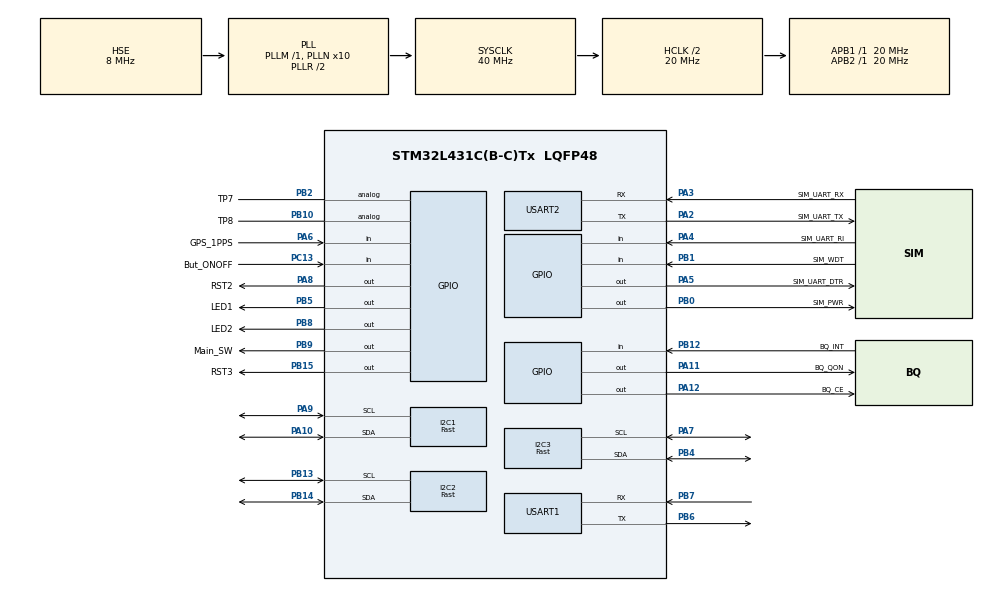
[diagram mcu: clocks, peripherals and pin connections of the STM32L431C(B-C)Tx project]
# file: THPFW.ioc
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ADC1.Channel-2\#ChannelRegularConversion=ADC_CHANNEL_TEMPSENSOR
ADC1.ClockPrescaler=ADC_CLOCK_ASYNC_DIV2
ADC1.ContinuousConvMode=ENABLE
ADC1.DMAContinuousRequests=ENABLE
ADC1.NbrOfConversion=1
ADC1.NbrOfConversionFlag=1
ADC1.OffsetNumber-2\#ChannelRegularConversion=ADC_OFFSET_NONE
ADC1.OversamplingMode=ENABLE
ADC1.Rank-2\#ChannelRegularConversion=1
ADC1.Ratio=ADC_OVERSAMPLING_RATIO_16
ADC1.SamplingTime-2\#ChannelRegularConversion=ADC_SAMPLETIME_640CYCLES_5
ADC1.master=1
CRC.CRCLength=CRC_POLYLENGTH_8B
CRC.DefaultInitValueUse=DEFAULT_INIT_VALUE_DISABLE
CRC.DefaultPolynomialUse=DEFAULT_POLYNOMIAL_DISABLE
CRC.GeneratingPolynomial=X5+X4+X0
CRC.InitValue=0xFF
Dma.ADC1.0.Direction=DMA_PERIPH_TO_MEMORY
Dma.ADC1.0.Instance=DMA1_Channel1
Dma.ADC1.0.MemDataAlignment=DMA_MDATAALIGN_HALFWORD
Dma.ADC1.0.MemInc=DMA_MINC_ENABLE
Dma.ADC1.0.Mode=DMA_CIRCULAR
Dma.ADC1.0.PeriphDataAlignment=DMA_PDATAALIGN_HALFWORD
Dma.ADC1.0.PeriphInc=DMA_PINC_DISABLE
Dma.ADC1.0.Priority=DMA_PRIORITY_LOW
Dma.Request0=ADC1
FREERTOS.INCLUDE_eTaskGetState=1
FREERTOS.INCLUDE_vTaskDelayUntil=1
FREERTOS.MEMORY_ALLOCATION=0
FREERTOS.Tasks01=defaultTask,-3,128,StartDefaultTask,Default,NULL,Dynamic,NULL,NULL;THPMainTask,0,512,THP_MainTask,As external,NULL,Dynamic,NULL,NULL
FREERTOS.configENABLE_FPU=1
FREERTOS.configMINIMAL_STACK_SIZE=128
FREERTOS.configTOTAL_HEAP_SIZE=16384
FREERTOS.configUSE_NEWLIB_REENTRANT=1
FREERTOS.configUSE_TASK_NOTIFICATIONS=1
FREERTOS.configUSE_TICKLESS_IDLE=1
I2C1.I2C_Speed_Mode=I2C_Fast
I2C1.Timing=0x00301347
I2C2.I2C_Speed_Mode=I2C_Fast
I2C2.NoStretchMode=I2C_NOSTRETCH_ENABLE
I2C2.Timing=0x00301347
I2C3.I2C_Speed_Mode=I2C_Fast
I2C3.NoStretchMode=I2C_NOSTRETCH_ENABLE
I2C3.Timing=0x00301347
Mcu.Family=STM32L4
Mcu.Name=STM32L431C(B-C)Tx
Mcu.Package=LQFP48
NVIC.DMA1_Channel1_IRQn=true\:5\:0\:false\:false\:true\:true\:false\:true\:true
NVIC.PriorityGroup=NVIC_PRIORITYGROUP_4
NVIC.RCC_IRQn=true\:5\:0\:false\:false\:false\:true\:true\:false\:false
NVIC.TIM7_IRQn=true\:15\:0\:false\:false\:true\:false\:false\:true\:true
NVIC.TimeBase=TIM7_IRQn
NVIC.TimeBaseIP=TIM7
NVIC.USART1_IRQn=true\:5\:0\:false\:true\:true\:1\:true\:true\:true\:true
NVIC.USART2_IRQn=true\:5\:0\:false\:true\:true\:2\:true\:true\:true\:true
PA0.GPIO_Label=Tamp
PA0.Mode=SYS_WakeUp0
PA0.Signal=SYS_WKUP1
PA10.GPIO_Pu=GPIO_PULLUP
PA10.Mode=I2C
PA10.Signal=I2C1_SDA
PA11.GPIO_Label=BQ_QON
PA11.Signal=GPIO_Output
PA12.GPIO_Label=BQ_CE
PA12.Signal=GPIO_Output
PA13\ (JTMS-SWDIO).Mode=Serial_Wire
PA13\ (JTMS-SWDIO).Signal=SYS_JTMS-SWDIO
PA14\ (JTCK-SWCLK).Mode=Serial_Wire
PA14\ (JTCK-SWCLK).Signal=SYS_JTCK-SWCLK
PA2.GPIO_Label=SIM_UART_TX
PA2.GPIO_Speed=GPIO_SPEED_FREQ_HIGH
PA2.Mode=Asynchronous
PA2.Signal=USART2_TX
PA3.GPIO_Label=SIM_UART_RX
PA3.GPIO_PuPd=GPIO_PULLUP
PA3.GPIO_Speed=GPIO_SPEED_FREQ_HIGH
PA3.Mode=Asynchronous
PA3.Signal=USART2_RX
PA4.GPIO_Label=SIM_UART_RI
PA4.Signal=GPIO_Input
PA5.GPIO_Label=SIM_UART_DTR
PA5.PinState=GPIO_PIN_SET
PA5.Signal=GPIO_Output
PA6.GPIO_Label=GPS_1PPS
PA6.GPIO_PuPd=GPIO_PULLUP
PA6.Signal=GPIO_Input
PA7.GPIO_Pu=GPIO_PULLUP
PA7.Mode=I2C
PA7.Signal=I2C3_SCL
PA8.GPIO_Label=RST2
PA8.GPIO_PuPd=GPIO_PULLUP
PA8.Signal=GPIO_Output
PA9.GPIO_Pu=GPIO_PULLUP
PA9.Mode=I2C
PA9.Signal=I2C1_SCL
PB0.GPIO_Label=SIM_PWR
PB0.Signal=GPIO_Output
PB1.GPIO_Label=SIM_WDT
PB1.GPIO_PuPd=GPIO_PULLUP
PB1.Signal=GPIO_Input
PB10.GPIO_Label=TP8
PB10.Signal=GPIO_Analog
PB12.GPIO_Label=BQ_INT
PB12.GPIO_PuPd=GPIO_PULLUP
PB12.Signal=GPIO_Input
PB13.GPIO_Pu=GPIO_PULLUP
PB13.Mode=I2C
PB13.Signal=I2C2_SCL
PB14.GPIO_Pu=GPIO_PULLUP
PB14.Mode=I2C
PB14.Signal=I2C2_SDA
PB15.GPIO_Label=RST3
PB15.GPIO_PuPd=GPIO_NOPULL
PB15.Signal=GPIO_Output
PB2.GPIO_Label=TP7
PB2.Signal=GPIO_Analog
PB4\ (NJTRST).GPIO_Pu=GPIO_PULLUP
PB4\ (NJTRST).Mode=I2C
PB4\ (NJTRST).Signal=I2C3_SDA
PB5.GPIO_Label=LED1
PB5.PinState=GPIO_PIN_SET
PB5.Signal=GPIO_Output
PB6.GPIO_Speed=GPIO_SPEED_FREQ_HIGH
PB6.Mode=Asynchronous
PB6.Signal=USART1_TX
PB7.GPIO_PuPd=GPIO_PULLUP
PB7.GPIO_Speed=GPIO_SPEED_FREQ_HIGH
PB7.Mode=Asynchronous
PB7.Signal=USART1_RX
PB8.GPIO_Label=LED2
PB8.PinState=GPIO_PIN_SET
PB8.Signal=GPIO_Output
PB9.GPIO_Label=Main_SW
PB9.GPIO_PuPd=GPIO_PULLDOWN
PB9.Signal=GPIO_Output
PC13.GPIO_Label=But_ONOFF
PC13.GPIO_PuPd=GPIO_PULLDOWN
PC13.Signal=GPIO_Input
PH0-OSC_IN\ (PH0).Mode=HSE-External-Oscillator
PH0-OSC_IN\ (PH0).Signal=RCC_OSC_IN
PH1-OSC_OUT\ (PH1).Mode=HSE-External-Oscillator
PH1-OSC_OUT\ (PH1).Signal=RCC_OSC_OUT
ProjectManager.HeapSize=0x200
ProjectManager.StackSize=0x400
ProjectManager.TargetToolchain=STM32CubeIDE
RCC.ADCFreq_Value=32000000
RCC.AHBCLKDivider=RCC_SYSCLK_DIV2
RCC.AHBFreq_Value=20000000
RCC.APB1Freq_Value=20000000
RCC.APB1TimFreq_Value=20000000
RCC.APB2Freq_Value=20000000
RCC.APB2TimFreq_Value=20000000
RCC.CortexFreq_Value=20000000
RCC.HCLKFreq_Value=20000000
RCC.HSE_VALUE=8000000
RCC.HSI48_VALUE=48000000
RCC.HSI_VALUE=16000000
RCC.I2C1CLockSelection=RCC_I2C1CLKSOURCE_SYSCLK
RCC.I2C2CLockSelection=RCC_I2C2CLKSOURCE_SYSCLK
RCC.I2C3CLockSelection=RCC_I2C3CLKSOURCE_SYSCLK
RCC.LSE_VALUE=32768
RCC.MSI_VALUE=4000000
RCC.PLLN=10
RCC.PLLSourceVirtual=RCC_PLLSOURCE_HSE
RCC.SYSCLKFreq_VALUE=40000000
RCC.SYSCLKSource=RCC_SYSCLKSOURCE_PLLCLK
RCC.USART1CLockSelection=RCC_USART1CLKSOURCE_SYSCLK
RCC.USART2CLockSelection=RCC_USART2CLKSOURCE_SYSCLK
RCC.VCOOutputFreq_Value=80000000
USART1.VirtualMode-Asynchronous=VM_ASYNC
USART2.VirtualMode-Asynchronous=VM_ASYNC
VP_ADC1_TempSens_Input.Mode=IN-TempSens
VP_CRC_VS_CRC.Mode=CRC_Activate
VP_FREERTOS_VS_CMSIS_V1.Mode=CMSIS_V1
VP_SYS_VS_tim7.Mode=TIM7
board=custom

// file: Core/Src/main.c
/* USER CODE BEGIN Header */
/**
  ******************************************************************************
  * @file           : main.c
  * @brief          : Main program body
  ******************************************************************************
  * @attention
  *
  * Copyright (c) 2024 STMicroelectronics.
  * All rights reserved.
  *
  * This software is licensed under terms that can be found in the LICENSE file
  * in the root directory of this software component.
  * If no LICENSE file comes with this software, it is provided AS-IS.
  *
  ******************************************************************************
  */
/* USER CODE END Header */
#include "main.h"
#include "cmsis_os.h"

ADC_HandleTypeDef hadc1;
DMA_HandleTypeDef hdma_adc1;

CRC_HandleTypeDef hcrc;

I2C_HandleTypeDef hi2c1;
I2C_HandleTypeDef hi2c2;
I2C_HandleTypeDef hi2c3;

UART_HandleTypeDef huart1;
UART_HandleTypeDef huart2;

osThreadId defaultTaskHandle;
osThreadId THPMainTaskHandle;

void SystemClock_Config(void);
static void MX_GPIO_Init(void);
static void MX_DMA_Init(void);
static void MX_ADC1_Init(void);
static void MX_I2C1_Init(void);
static void MX_I2C2_Init(void);
static void MX_I2C3_Init(void);
static void MX_USART1_UART_Init(void);
static void MX_USART2_UART_Init(void);
static void MX_CRC_Init(void);
void StartDefaultTask(void const * argument);
extern void THP_MainTask(void const * argument);

static void MX_NVIC_Init(void);

int main(void)
{

  /* MCU Configuration--------------------------------------------------------*/

  /* Reset of all peripherals, Initializes the Flash interface and the Systick. */
  HAL_Init();

  /* Configure the system clock */
  SystemClock_Config();

  /* Initialize all configured peripherals */
  MX_GPIO_Init();
  MX_DMA_Init();
  MX_ADC1_Init();
  MX_I2C1_Init();
  MX_I2C2_Init();
  MX_I2C3_Init();
  MX_USART1_UART_Init();
  MX_USART2_UART_Init();
  MX_CRC_Init();

  /* Initialize interrupts */
  MX_NVIC_Init();

  /* Create the thread(s) */
  /* definition and creation of defaultTask */
  osThreadDef(defaultTask, StartDefaultTask, osPriorityIdle, 0, 128);
  defaultTaskHandle = osThreadCreate(osThread(defaultTask), NULL);

  /* definition and creation of THPMainTask */
  osThreadDef(THPMainTask, THP_MainTask, osPriorityNormal, 0, 512);
  THPMainTaskHandle = osThreadCreate(osThread(THPMainTask), NULL);

  /* Start scheduler */
  osKernelStart();
  /* We should never get here as control is now taken by the scheduler */
  /* Infinite loop */
  while (1)
  {

  }
}

void SystemClock_Config(void)
{
  RCC_OscInitTypeDef RCC_OscInitStruct = {0};
  RCC_ClkInitTypeDef RCC_ClkInitStruct = {0};

  /** Configure the main internal regulator output voltage
  */
  if (HAL_PWREx_ControlVoltageScaling(PWR_REGULATOR_VOLTAGE_SCALE1) != HAL_OK)
  {
    Error_Handler();
  }

  /** Initializes the RCC Oscillators according to the specified parameters
  * in the RCC_OscInitTypeDef structure.
  */
  RCC_OscInitStruct.OscillatorType = RCC_OSCILLATORTYPE_HSE;
  RCC_OscInitStruct.HSEState = RCC_HSE_ON;
  RCC_OscInitStruct.PLL.PLLState = RCC_PLL_ON;
  RCC_OscInitStruct.PLL.PLLSource = RCC_PLLSOURCE_HSE;
  RCC_OscInitStruct.PLL.PLLM = 1;
  RCC_OscInitStruct.PLL.PLLN = 10;
  RCC_OscInitStruct.PLL.PLLP = RCC_PLLP_DIV7;
  RCC_OscInitStruct.PLL.PLLQ = RCC_PLLQ_DIV2;
  RCC_OscInitStruct.PLL.PLLR = RCC_PLLR_DIV2;
  if (HAL_RCC_OscConfig(&RCC_OscInitStruct) != HAL_OK)
  {
    Error_Handler();
  }

  /** Initializes the CPU, AHB and APB buses clocks
  */
  RCC_ClkInitStruct.ClockType = RCC_CLOCKTYPE_HCLK|RCC_CLOCKTYPE_SYSCLK
                              |RCC_CLOCKTYPE_PCLK1|RCC_CLOCKTYPE_PCLK2;
  RCC_ClkInitStruct.SYSCLKSource = RCC_SYSCLKSOURCE_PLLCLK;
  RCC_ClkInitStruct.AHBCLKDivider = RCC_SYSCLK_DIV2;
  RCC_ClkInitStruct.APB1CLKDivider = RCC_HCLK_DIV1;
  RCC_ClkInitStruct.APB2CLKDivider = RCC_HCLK_DIV1;

  if (HAL_RCC_ClockConfig(&RCC_ClkInitStruct, FLASH_LATENCY_1) != HAL_OK)
  {
    Error_Handler();
  }
}

/**
  * @brief NVIC Configuration.
  * @retval None
  */
static void MX_NVIC_Init(void)
{
  /* USART1_IRQn interrupt configuration */
  HAL_NVIC_SetPriority(USART1_IRQn, 5, 0);
  HAL_NVIC_EnableIRQ(USART1_IRQn);
  /* USART2_IRQn interrupt configuration */
  HAL_NVIC_SetPriority(USART2_IRQn, 5, 0);
  HAL_NVIC_EnableIRQ(USART2_IRQn);
}

static void MX_ADC1_Init(void)
{

  ADC_ChannelConfTypeDef sConfig = {0};

  /** Common config
  */
  hadc1.Instance = ADC1;
  hadc1.Init.ClockPrescaler = ADC_CLOCK_ASYNC_DIV2;
  hadc1.Init.Resolution = ADC_RESOLUTION_12B;
  hadc1.Init.DataAlign = ADC_DATAALIGN_RIGHT;
  hadc1.Init.ScanConvMode = ADC_SCAN_DISABLE;
  hadc1.Init.EOCSelection = ADC_EOC_SINGLE_CONV;
  hadc1.Init.LowPowerAutoWait = DISABLE;
  hadc1.Init.ContinuousConvMode = ENABLE;
  hadc1.Init.NbrOfConversion = 1;
  hadc1.Init.DiscontinuousConvMode = DISABLE;
  hadc1.Init.ExternalTrigConv = ADC_SOFTWARE_START;
  hadc1.Init.ExternalTrigConvEdge = ADC_EXTERNALTRIGCONVEDGE_NONE;
  hadc1.Init.DMAContinuousRequests = ENABLE;
  hadc1.Init.Overrun = ADC_OVR_DATA_PRESERVED;
  hadc1.Init.OversamplingMode = ENABLE;
  hadc1.Init.Oversampling.Ratio = ADC_OVERSAMPLING_RATIO_16;
  hadc1.Init.Oversampling.RightBitShift = ADC_RIGHTBITSHIFT_NONE;
  hadc1.Init.Oversampling.TriggeredMode = ADC_TRIGGEREDMODE_SINGLE_TRIGGER;
  hadc1.Init.Oversampling.OversamplingStopReset = ADC_REGOVERSAMPLING_CONTINUED_MODE;
  if (HAL_ADC_Init(&hadc1) != HAL_OK)
  {
    Error_Handler();
  }

  /** Configure Regular Channel
  */
  sConfig.Channel = ADC_CHANNEL_TEMPSENSOR;
  sConfig.Rank = ADC_REGULAR_RANK_1;
  sConfig.SamplingTime = ADC_SAMPLETIME_640CYCLES_5;
  sConfig.SingleDiff = ADC_SINGLE_ENDED;
  sConfig.OffsetNumber = ADC_OFFSET_NONE;
  sConfig.Offset = 0;
  if (HAL_ADC_ConfigChannel(&hadc1, &sConfig) != HAL_OK)
  {
    Error_Handler();
  }

}

static void MX_CRC_Init(void)
{

  hcrc.Instance = CRC;
  hcrc.Init.DefaultPolynomialUse = DEFAULT_POLYNOMIAL_DISABLE;
  hcrc.Init.DefaultInitValueUse = DEFAULT_INIT_VALUE_DISABLE;
  hcrc.Init.GeneratingPolynomial = 49;
  hcrc.Init.CRCLength = CRC_POLYLENGTH_8B;
  hcrc.Init.InitValue = 0xFF;
  hcrc.Init.InputDataInversionMode = CRC_INPUTDATA_INVERSION_NONE;
  hcrc.Init.OutputDataInversionMode = CRC_OUTPUTDATA_INVERSION_DISABLE;
  hcrc.InputDataFormat = CRC_INPUTDATA_FORMAT_BYTES;
  if (HAL_CRC_Init(&hcrc) != HAL_OK)
  {
    Error_Handler();
  }

}

static void MX_I2C1_Init(void)
{

  hi2c1.Instance = I2C1;
  hi2c1.Init.Timing = 0x00301347;
  hi2c1.Init.OwnAddress1 = 0;
  hi2c1.Init.AddressingMode = I2C_ADDRESSINGMODE_7BIT;
  hi2c1.Init.DualAddressMode = I2C_DUALADDRESS_DISABLE;
  hi2c1.Init.OwnAddress2 = 0;
  hi2c1.Init.OwnAddress2Masks = I2C_OA2_NOMASK;
  hi2c1.Init.GeneralCallMode = I2C_GENERALCALL_DISABLE;
  hi2c1.Init.NoStretchMode = I2C_NOSTRETCH_DISABLE;
  if (HAL_I2C_Init(&hi2c1) != HAL_OK)
  {
    Error_Handler();
  }

  /** Configure Analogue filter
  */
  if (HAL_I2CEx_ConfigAnalogFilter(&hi2c1, I2C_ANALOGFILTER_ENABLE) != HAL_OK)
  {
    Error_Handler();
  }

  /** Configure Digital filter
  */
  if (HAL_I2CEx_ConfigDigitalFilter(&hi2c1, 0) != HAL_OK)
  {
    Error_Handler();
  }

}

static void MX_I2C2_Init(void)
{

  hi2c2.Instance = I2C2;
  hi2c2.Init.Timing = 0x00301347;
  hi2c2.Init.OwnAddress1 = 0;
  hi2c2.Init.AddressingMode = I2C_ADDRESSINGMODE_7BIT;
  hi2c2.Init.DualAddressMode = I2C_DUALADDRESS_DISABLE;
  hi2c2.Init.OwnAddress2 = 0;
  hi2c2.Init.OwnAddress2Masks = I2C_OA2_NOMASK;
  hi2c2.Init.GeneralCallMode = I2C_GENERALCALL_DISABLE;
  hi2c2.Init.NoStretchMode = I2C_NOSTRETCH_ENABLE;
  if (HAL_I2C_Init(&hi2c2) != HAL_OK)
  {
    Error_Handler();
  }

  /** Configure Analogue filter
  */
  if (HAL_I2CEx_ConfigAnalogFilter(&hi2c2, I2C_ANALOGFILTER_ENABLE) != HAL_OK)
  {
    Error_Handler();
  }

  /** Configure Digital filter
  */
  if (HAL_I2CEx_ConfigDigitalFilter(&hi2c2, 0) != HAL_OK)
  {
    Error_Handler();
  }

}

static void MX_I2C3_Init(void)
{

  hi2c3.Instance = I2C3;
  hi2c3.Init.Timing = 0x00301347;
  hi2c3.Init.OwnAddress1 = 0;
  hi2c3.Init.AddressingMode = I2C_ADDRESSINGMODE_7BIT;
  hi2c3.Init.DualAddressMode = I2C_DUALADDRESS_DISABLE;
  hi2c3.Init.OwnAddress2 = 0;
  hi2c3.Init.OwnAddress2Masks = I2C_OA2_NOMASK;
  hi2c3.Init.GeneralCallMode = I2C_GENERALCALL_DISABLE;
  hi2c3.Init.NoStretchMode = I2C_NOSTRETCH_ENABLE;
  if (HAL_I2C_Init(&hi2c3) != HAL_OK)
  {
    Error_Handler();
  }

  /** Configure Analogue filter
  */
  if (HAL_I2CEx_ConfigAnalogFilter(&hi2c3, I2C_ANALOGFILTER_ENABLE) != HAL_OK)
  {
    Error_Handler();
  }

  /** Configure Digital filter
  */
  if (HAL_I2CEx_ConfigDigitalFilter(&hi2c3, 0) != HAL_OK)
  {
    Error_Handler();
  }

}

static void MX_USART1_UART_Init(void)
{

  huart1.Instance = USART1;
  huart1.Init.BaudRate = 115200;
  huart1.Init.WordLength = UART_WORDLENGTH_8B;
  huart1.Init.StopBits = UART_STOPBITS_1;
  huart1.Init.Parity = UART_PARITY_NONE;
  huart1.Init.Mode = UART_MODE_TX_RX;
  huart1.Init.HwFlowCtl = UART_HWCONTROL_NONE;
  huart1.Init.OverSampling = UART_OVERSAMPLING_16;
  huart1.Init.OneBitSampling = UART_ONE_BIT_SAMPLE_DISABLE;
  huart1.AdvancedInit.AdvFeatureInit = UART_ADVFEATURE_NO_INIT;
  if (HAL_UART_Init(&huart1) != HAL_OK)
  {
    Error_Handler();
  }

}

static void MX_USART2_UART_Init(void)
{

  huart2.Instance = USART2;
  huart2.Init.BaudRate = 115200;
  huart2.Init.WordLength = UART_WORDLENGTH_8B;
  huart2.Init.StopBits = UART_STOPBITS_1;
  huart2.Init.Parity = UART_PARITY_NONE;
  huart2.Init.Mode = UART_MODE_TX_RX;
  huart2.Init.HwFlowCtl = UART_HWCONTROL_NONE;
  huart2.Init.OverSampling = UART_OVERSAMPLING_16;
  huart2.Init.OneBitSampling = UART_ONE_BIT_SAMPLE_DISABLE;
  huart2.AdvancedInit.AdvFeatureInit = UART_ADVFEATURE_NO_INIT;
  if (HAL_UART_Init(&huart2) != HAL_OK)
  {
    Error_Handler();
  }

}

static void MX_DMA_Init(void)
{

  /* DMA controller clock enable */
  __HAL_RCC_DMA1_CLK_ENABLE();

  /* DMA interrupt init */
  /* DMA1_Channel1_IRQn interrupt configuration */
  HAL_NVIC_SetPriority(DMA1_Channel1_IRQn, 5, 0);
  HAL_NVIC_EnableIRQ(DMA1_Channel1_IRQn);

}

static void MX_GPIO_Init(void)
{
  GPIO_InitTypeDef GPIO_InitStruct = {0};

  /* GPIO Ports Clock Enable */
  __HAL_RCC_GPIOC_CLK_ENABLE();
  __HAL_RCC_GPIOH_CLK_ENABLE();
  __HAL_RCC_GPIOA_CLK_ENABLE();
  __HAL_RCC_GPIOB_CLK_ENABLE();

  /*Configure GPIO pin Output Level */
  HAL_GPIO_WritePin(SIM_UART_DTR_GPIO_Port, SIM_UART_DTR_Pin, GPIO_PIN_SET);

  /*Configure GPIO pin Output Level */
  HAL_GPIO_WritePin(GPIOB, SIM_PWR_Pin|RST3_Pin|Main_SW_Pin, GPIO_PIN_RESET);

  /*Configure GPIO pin Output Level */
  HAL_GPIO_WritePin(GPIOA, RST2_Pin|BQ_QON_Pin|BQ_CE_Pin, GPIO_PIN_RESET);

  /*Configure GPIO pin Output Level */
  HAL_GPIO_WritePin(GPIOB, LED1_Pin|LED2_Pin, GPIO_PIN_SET);

  /*Configure GPIO pin : But_ONOFF_Pin */
  GPIO_InitStruct.Pin = But_ONOFF_Pin;
  GPIO_InitStruct.Mode = GPIO_MODE_INPUT;
  GPIO_InitStruct.Pull = GPIO_PULLDOWN;
  HAL_GPIO_Init(But_ONOFF_GPIO_Port, &GPIO_InitStruct);

  /*Configure GPIO pins : PC14 PC15 */
  GPIO_InitStruct.Pin = GPIO_PIN_14|GPIO_PIN_15;
  GPIO_InitStruct.Mode = GPIO_MODE_ANALOG;
  GPIO_InitStruct.Pull = GPIO_NOPULL;
  HAL_GPIO_Init(GPIOC, &GPIO_InitStruct);

  /*Configure GPIO pins : PA1 PA15 */
  GPIO_InitStruct.Pin = GPIO_PIN_1|GPIO_PIN_15;
  GPIO_InitStruct.Mode = GPIO_MODE_ANALOG;
  GPIO_InitStruct.Pull = GPIO_NOPULL;
  HAL_GPIO_Init(GPIOA, &GPIO_InitStruct);

  /*Configure GPIO pin : SIM_UART_RI_Pin */
  GPIO_InitStruct.Pin = SIM_UART_RI_Pin;
  GPIO_InitStruct.Mode = GPIO_MODE_INPUT;
  GPIO_InitStruct.Pull = GPIO_NOPULL;
  HAL_GPIO_Init(SIM_UART_RI_GPIO_Port, &GPIO_InitStruct);

  /*Configure GPIO pins : SIM_UART_DTR_Pin BQ_QON_Pin BQ_CE_Pin */
  GPIO_InitStruct.Pin = SIM_UART_DTR_Pin|BQ_QON_Pin|BQ_CE_Pin;
  GPIO_InitStruct.Mode = GPIO_MODE_OUTPUT_PP;
  GPIO_InitStruct.Pull = GPIO_NOPULL;
  GPIO_InitStruct.Speed = GPIO_SPEED_FREQ_LOW;
  HAL_GPIO_Init(GPIOA, &GPIO_InitStruct);

  /*Configure GPIO pin : GPS_1PPS_Pin */
  GPIO_InitStruct.Pin = GPS_1PPS_Pin;
  GPIO_InitStruct.Mode = GPIO_MODE_INPUT;
  GPIO_InitStruct.Pull = GPIO_PULLUP;
  HAL_GPIO_Init(GPS_1PPS_GPIO_Port, &GPIO_InitStruct);

  /*Configure GPIO pins : SIM_PWR_Pin RST3_Pin LED1_Pin LED2_Pin */
  GPIO_InitStruct.Pin = SIM_PWR_Pin|RST3_Pin|LED1_Pin|LED2_Pin;
  GPIO_InitStruct.Mode = GPIO_MODE_OUTPUT_PP;
  GPIO_InitStruct.Pull = GPIO_NOPULL;
  GPIO_InitStruct.Speed = GPIO_SPEED_FREQ_LOW;
  HAL_GPIO_Init(GPIOB, &GPIO_InitStruct);

  /*Configure GPIO pins : SIM_WDT_Pin BQ_INT_Pin */
  GPIO_InitStruct.Pin = SIM_WDT_Pin|BQ_INT_Pin;
  GPIO_InitStruct.Mode = GPIO_MODE_INPUT;
  GPIO_InitStruct.Pull = GPIO_PULLUP;
  HAL_GPIO_Init(GPIOB, &GPIO_InitStruct);

  /*Configure GPIO pins : TP7_Pin TP8_Pin PB11 PB3 */
  GPIO_InitStruct.Pin = TP7_Pin|TP8_Pin|GPIO_PIN_11|GPIO_PIN_3;
  GPIO_InitStruct.Mode = GPIO_MODE_ANALOG;
  GPIO_InitStruct.Pull = GPIO_NOPULL;
  HAL_GPIO_Init(GPIOB, &GPIO_InitStruct);

  /*Configure GPIO pin : RST2_Pin */
  GPIO_InitStruct.Pin = RST2_Pin;
  GPIO_InitStruct.Mode = GPIO_MODE_OUTPUT_PP;
  GPIO_InitStruct.Pull = GPIO_PULLUP;
  GPIO_InitStruct.Speed = GPIO_SPEED_FREQ_LOW;
  HAL_GPIO_Init(RST2_GPIO_Port, &GPIO_InitStruct);

  /*Configure GPIO pin : PH3 */
  GPIO_InitStruct.Pin = GPIO_PIN_3;
  GPIO_InitStruct.Mode = GPIO_MODE_ANALOG;
  GPIO_InitStruct.Pull = GPIO_NOPULL;
  HAL_GPIO_Init(GPIOH, &GPIO_InitStruct);

  /*Configure GPIO pin : Main_SW_Pin */
  GPIO_InitStruct.Pin = Main_SW_Pin;
  GPIO_InitStruct.Mode = GPIO_MODE_OUTPUT_PP;
  GPIO_InitStruct.Pull = GPIO_PULLDOWN;
  GPIO_InitStruct.Speed = GPIO_SPEED_FREQ_LOW;
  HAL_GPIO_Init(Main_SW_GPIO_Port, &GPIO_InitStruct);

}

void StartDefaultTask(void const * argument)
{
  /* USER CODE BEGIN 5 */
  /* Infinite loop */
  for(;;)
  {
    osDelay(1);
    __WFI();
  }
  /* USER CODE END 5 */
}

void HAL_TIM_PeriodElapsedCallback(TIM_HandleTypeDef *htim)
{
  if (htim->Instance == TIM7) {
    HAL_IncTick();
  }
  /* USER CODE BEGIN Callback 1 */
  if (htim->Instance == TIM7) {
	  HAL_SYSTICK_Callback();
  }

  /* USER CODE END Callback 1 */
}

void Error_Handler(void)
{
  __disable_irq();
  while (1)
  {
  }
}

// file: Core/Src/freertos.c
/* USER CODE BEGIN Header */
/**
  ******************************************************************************
  * File Name          : freertos.c
  * Description        : Code for freertos applications
  ******************************************************************************
  * @attention
  *
  * Copyright (c) 2024 STMicroelectronics.
  * All rights reserved.
  *
  * This software is licensed under terms that can be found in the LICENSE file
  * in the root directory of this software component.
  * If no LICENSE file comes with this software, it is provided AS-IS.
  *
  ******************************************************************************
  */
/* USER CODE END Header */

#include "FreeRTOS.h"
#include "task.h"
#include "main.h"

/* USER CODE BEGIN PREPOSTSLEEP */
__weak void PreSleepProcessing(uint32_t ulExpectedIdleTime)
{
/* place for user code */
}

__weak void PostSleepProcessing(uint32_t ulExpectedIdleTime)
{
/* place for user code */
}
/* USER CODE END PREPOSTSLEEP */
